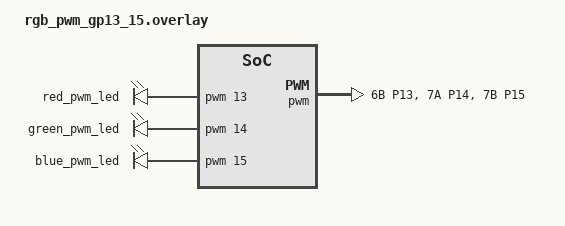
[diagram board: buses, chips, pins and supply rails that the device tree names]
/* SPDX-License-Identifier: Apache-2.0 OR MIT */
/*
 * samples/basic/rgb_led's red, green and blue PWM LEDs on GP13 (PWM 6B),
 * GP14 (7A) and GP15 (7B), 20 ms periods; the dividers as the Pico's own
 * blinky_pwm overlay sets slice 4's.
 */
#include <zephyr/dt-bindings/pwm/pwm.h>

/ {
	rgb_pwm_leds {
		compatible = "pwm-leds";

		red_pwm_led: red_pwm_led {
			pwms = <&pwm 13 PWM_MSEC(20) PWM_POLARITY_NORMAL>;
		};
		green_pwm_led: green_pwm_led {
			pwms = <&pwm 14 PWM_MSEC(20) PWM_POLARITY_NORMAL>;
		};
		blue_pwm_led: blue_pwm_led {
			pwms = <&pwm 15 PWM_MSEC(20) PWM_POLARITY_NORMAL>;
		};
	};

	aliases {
		red-pwm-led = &red_pwm_led;
		green-pwm-led = &green_pwm_led;
		blue-pwm-led = &blue_pwm_led;
	};
};

&pinctrl {
	pwm_gp13_15: pwm_gp13_15 {
		group1 {
			pinmux = <PWM_6B_P13>, <PWM_7A_P14>, <PWM_7B_P15>;
		};
	};
};

&pwm {
	status = "okay";
	pinctrl-0 = <&pwm_gp13_15>;
	pinctrl-names = "default";
	divider-int-6 = <255>;
	divider-int-7 = <255>;
};
